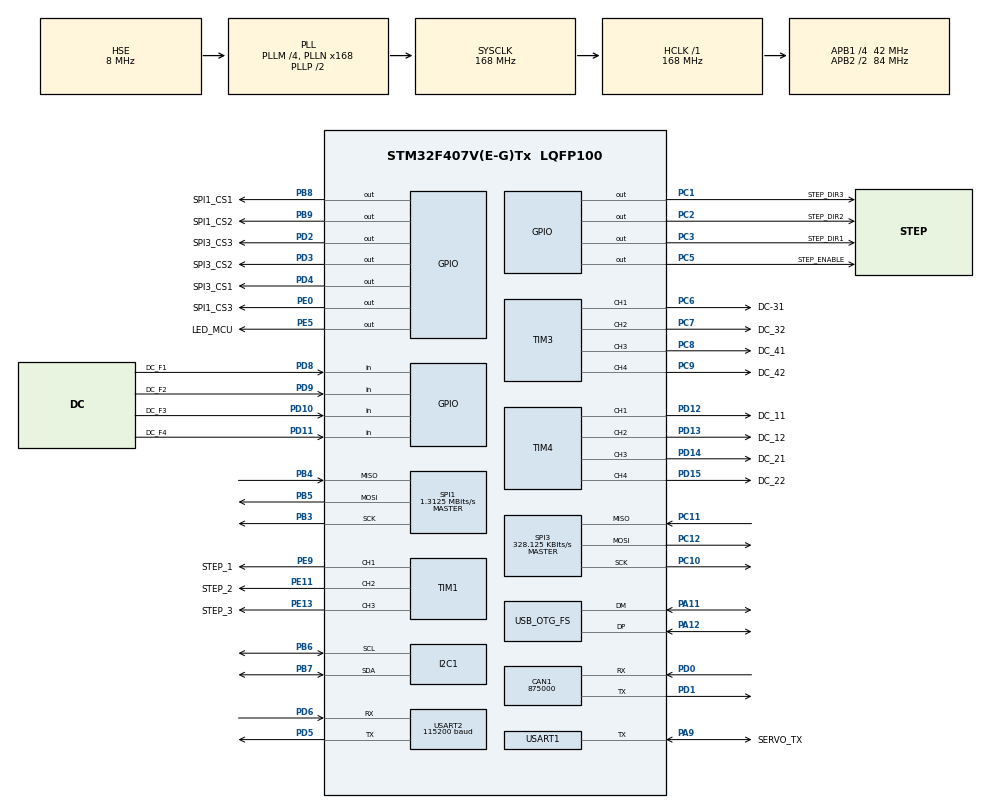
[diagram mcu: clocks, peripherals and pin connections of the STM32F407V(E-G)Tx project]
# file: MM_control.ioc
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CAN1.CalculateBaudRate=875000
CAN1.CalculateTimeBit=1142
CAN1.CalculateTimeQuantum=380.95238095238096
Dma.Request0=USART1_TX
Dma.Request1=USART1_RX
Dma.Request2=SPI1_RX
Dma.Request3=SPI1_TX
Dma.SPI1_RX.2.Direction=DMA_PERIPH_TO_MEMORY
Dma.SPI1_RX.2.FIFOMode=DMA_FIFOMODE_DISABLE
Dma.SPI1_RX.2.Instance=DMA2_Stream0
Dma.SPI1_RX.2.MemDataAlignment=DMA_MDATAALIGN_BYTE
Dma.SPI1_RX.2.MemInc=DMA_MINC_ENABLE
Dma.SPI1_RX.2.Mode=DMA_NORMAL
Dma.SPI1_RX.2.PeriphDataAlignment=DMA_PDATAALIGN_BYTE
Dma.SPI1_RX.2.PeriphInc=DMA_PINC_DISABLE
Dma.SPI1_RX.2.Priority=DMA_PRIORITY_HIGH
Dma.SPI1_TX.3.Direction=DMA_MEMORY_TO_PERIPH
Dma.SPI1_TX.3.FIFOMode=DMA_FIFOMODE_DISABLE
Dma.SPI1_TX.3.Instance=DMA2_Stream3
Dma.SPI1_TX.3.MemDataAlignment=DMA_MDATAALIGN_BYTE
Dma.SPI1_TX.3.MemInc=DMA_MINC_ENABLE
Dma.SPI1_TX.3.Mode=DMA_NORMAL
Dma.SPI1_TX.3.PeriphDataAlignment=DMA_PDATAALIGN_BYTE
Dma.SPI1_TX.3.PeriphInc=DMA_PINC_DISABLE
Dma.SPI1_TX.3.Priority=DMA_PRIORITY_HIGH
Dma.USART1_RX.1.Direction=DMA_PERIPH_TO_MEMORY
Dma.USART1_RX.1.FIFOMode=DMA_FIFOMODE_DISABLE
Dma.USART1_RX.1.Instance=DMA2_Stream2
Dma.USART1_RX.1.MemDataAlignment=DMA_MDATAALIGN_BYTE
Dma.USART1_RX.1.MemInc=DMA_MINC_ENABLE
Dma.USART1_RX.1.Mode=DMA_NORMAL
Dma.USART1_RX.1.PeriphDataAlignment=DMA_PDATAALIGN_BYTE
Dma.USART1_RX.1.PeriphInc=DMA_PINC_DISABLE
Dma.USART1_RX.1.Priority=DMA_PRIORITY_LOW
Dma.USART1_TX.0.Direction=DMA_MEMORY_TO_PERIPH
Dma.USART1_TX.0.FIFOMode=DMA_FIFOMODE_DISABLE
Dma.USART1_TX.0.Instance=DMA2_Stream7
Dma.USART1_TX.0.MemDataAlignment=DMA_MDATAALIGN_BYTE
Dma.USART1_TX.0.MemInc=DMA_MINC_ENABLE
Dma.USART1_TX.0.Mode=DMA_NORMAL
Dma.USART1_TX.0.PeriphDataAlignment=DMA_PDATAALIGN_BYTE
Dma.USART1_TX.0.PeriphInc=DMA_PINC_DISABLE
Dma.USART1_TX.0.Priority=DMA_PRIORITY_LOW
FREERTOS.Tasks01=Task1,24,128,StartDefaultTask,Default,NULL,Dynamic,NULL,NULL
FREERTOS.configENABLE_FPU=1
Mcu.Family=STM32F4
Mcu.Name=STM32F407V(E-G)Tx
Mcu.Package=LQFP100
NVIC.DMA2_Stream0_IRQn=true\:6\:0\:true\:false\:true\:true\:false\:true\:true
NVIC.DMA2_Stream2_IRQn=true\:5\:0\:false\:false\:true\:true\:false\:true\:true
NVIC.DMA2_Stream3_IRQn=true\:5\:0\:false\:false\:true\:true\:false\:true\:true
NVIC.DMA2_Stream7_IRQn=true\:5\:0\:false\:false\:true\:true\:false\:true\:true
NVIC.OTG_FS_IRQn=true\:6\:0\:true\:false\:true\:true\:false\:true\:true
NVIC.PriorityGroup=NVIC_PRIORITYGROUP_4
NVIC.SPI1_IRQn=true\:5\:0\:false\:false\:true\:true\:true\:true\:true
NVIC.SPI3_IRQn=true\:5\:0\:false\:false\:true\:true\:true\:true\:true
NVIC.TIM1_BRK_TIM9_IRQn=true\:6\:0\:true\:false\:true\:true\:true\:true\:true
NVIC.TIM1_UP_TIM10_IRQn=true\:5\:0\:false\:false\:true\:true\:true\:true\:true
NVIC.TIM3_IRQn=true\:6\:0\:true\:false\:true\:true\:true\:true\:true
NVIC.TIM4_IRQn=true\:5\:0\:false\:false\:true\:true\:true\:true\:true
NVIC.TIM8_TRG_COM_TIM14_IRQn=true\:5\:0\:false\:false\:true\:false\:false\:true\:true
NVIC.TimeBase=TIM8_TRG_COM_TIM14_IRQn
NVIC.TimeBaseIP=TIM14
NVIC.USART1_IRQn=true\:5\:0\:false\:false\:true\:true\:true\:true\:true
NVIC.USART2_IRQn=true\:5\:0\:false\:false\:true\:true\:true\:true\:true
PA11.Mode=Device_Only
PA11.Signal=USB_OTG_FS_DM
PA12.Mode=Device_Only
PA12.Signal=USB_OTG_FS_DP
PA13.Mode=Serial_Wire
PA13.Signal=SYS_JTMS-SWDIO
PA14.Mode=Serial_Wire
PA14.Signal=SYS_JTCK-SWCLK
PA9.GPIO_Label=SERVO_TX
PA9.Mode=Half_duplex(single_wire_mode)
PA9.Signal=USART1_TX
PB3.Mode=Full_Duplex_Master
PB3.Signal=SPI1_SCK
PB4.Mode=Full_Duplex_Master
PB4.Signal=SPI1_MISO
PB5.Mode=Full_Duplex_Master
PB5.Signal=SPI1_MOSI
PB6.Mode=I2C
PB6.Signal=I2C1_SCL
PB7.Mode=I2C
PB7.Signal=I2C1_SDA
PB8.GPIO_Label=SPI1_CS1
PB8.GPIO_Speed=GPIO_SPEED_FREQ_HIGH
PB8.PinState=GPIO_PIN_SET
PB8.Signal=GPIO_Output
PB9.GPIO_Label=SPI1_CS2
PB9.GPIO_Speed=GPIO_SPEED_FREQ_HIGH
PB9.PinState=GPIO_PIN_SET
PB9.Signal=GPIO_Output
PC1.GPIO_Label=STEP_DIR3
PC1.Signal=GPIO_Output
PC10.Mode=Full_Duplex_Master
PC10.Signal=SPI3_SCK
PC11.GPIO_PuPd=GPIO_PULLUP
PC11.Mode=Full_Duplex_Master
PC11.Signal=SPI3_MISO
PC12.Mode=Full_Duplex_Master
PC12.Signal=SPI3_MOSI
PC2.GPIO_Label=STEP_DIR2
PC2.Signal=GPIO_Output
PC3.GPIO_Label=STEP_DIR1
PC3.Signal=GPIO_Output
PC5.GPIO_Label=STEP_ENABLE
PC5.Signal=GPIO_Output
PC6.GPIO_Label=DC-31
PC6.Signal=S_TIM3_CH1
PC7.GPIO_Label=DC_32
PC7.Signal=S_TIM3_CH2
PC8.GPIO_Label=DC_41
PC8.Signal=S_TIM3_CH3
PC9.GPIO_Label=DC_42
PC9.Signal=S_TIM3_CH4
PD0.Mode=CAN_Activate
PD0.Signal=CAN1_RX
PD1.Mode=CAN_Activate
PD1.Signal=CAN1_TX
PD10.GPIO_Label=DC_F3
PD10.GPIO_PuPd=GPIO_PULLUP
PD10.Signal=GPIO_Input
PD11.GPIO_Label=DC_F4
PD11.GPIO_PuPd=GPIO_PULLUP
PD11.Signal=GPIO_Input
PD12.GPIO_Label=DC_11
PD12.Signal=S_TIM4_CH1
PD13.GPIO_Label=DC_12
PD13.Signal=S_TIM4_CH2
PD14.GPIO_Label=DC_21
PD14.Signal=S_TIM4_CH3
PD15.GPIO_Label=DC_22
PD15.Signal=S_TIM4_CH4
PD2.GPIO_Label=SPI3_CS3
PD2.GPIO_Speed=GPIO_SPEED_FREQ_HIGH
PD2.PinState=GPIO_PIN_SET
PD2.Signal=GPIO_Output
PD3.GPIO_Label=SPI3_CS2
PD3.GPIO_Speed=GPIO_SPEED_FREQ_HIGH
PD3.PinState=GPIO_PIN_SET
PD3.Signal=GPIO_Output
PD4.GPIO_Label=SPI3_CS1
PD4.GPIO_Speed=GPIO_SPEED_FREQ_HIGH
PD4.PinState=GPIO_PIN_SET
PD4.Signal=GPIO_Output
PD5.GPIO_PuPd=GPIO_PULLUP
PD5.Mode=Asynchronous
PD5.Signal=USART2_TX
PD6.GPIO_PuPd=GPIO_PULLUP
PD6.Mode=Asynchronous
PD6.Signal=USART2_RX
PD8.GPIO_Label=DC_F1
PD8.GPIO_PuPd=GPIO_PULLUP
PD8.Signal=GPIO_Input
PD9.GPIO_Label=DC_F2
PD9.GPIO_PuPd=GPIO_PULLUP
PD9.Signal=GPIO_Input
PE0.GPIO_Label=SPI1_CS3
PE0.GPIO_Speed=GPIO_SPEED_FREQ_HIGH
PE0.PinState=GPIO_PIN_SET
PE0.Signal=GPIO_Output
PE11.GPIO_Label=STEP_2
PE11.Signal=S_TIM1_CH2
PE13.GPIO_Label=STEP_3
PE13.Signal=S_TIM1_CH3
PE5.GPIO_Label=LED_MCU
PE5.Signal=GPIO_Output
PE9.GPIO_Label=STEP_1
PE9.Signal=S_TIM1_CH1
PH0-OSC_IN.Mode=HSE-External-Oscillator
PH0-OSC_IN.Signal=RCC_OSC_IN
PH1-OSC_OUT.Mode=HSE-External-Oscillator
PH1-OSC_OUT.Signal=RCC_OSC_OUT
ProjectManager.HeapSize=0x200
ProjectManager.StackSize=0x400
ProjectManager.TargetToolchain=CMake
RCC.48MHZClocksFreq_Value=48000000
RCC.AHBFreq_Value=168000000
RCC.APB1CLKDivider=RCC_HCLK_DIV4
RCC.APB1Freq_Value=42000000
RCC.APB1TimFreq_Value=84000000
RCC.APB2CLKDivider=RCC_HCLK_DIV2
RCC.APB2Freq_Value=84000000
RCC.APB2TimFreq_Value=168000000
RCC.CortexFreq_Value=168000000
RCC.HCLKFreq_Value=168000000
RCC.HSE_VALUE=8000000
RCC.HSI_VALUE=16000000
RCC.LSE_VALUE=32768
RCC.PLLM=4
RCC.PLLN=168
RCC.PLLQ=7
RCC.SYSCLKFreq_VALUE=168000000
RCC.SYSCLKSource=RCC_SYSCLKSOURCE_PLLCLK
RCC.VCOOutputFreq_Value=336000000
SH.S_TIM1_CH1.0=TIM1_CH1,PWM Generation1 CH1
SH.S_TIM1_CH2.0=TIM1_CH2,PWM Generation2 CH2
SH.S_TIM1_CH3.0=TIM1_CH3,PWM Generation3 CH3
SH.S_TIM3_CH1.0=TIM3_CH1,PWM Generation1 CH1
SH.S_TIM3_CH2.0=TIM3_CH2,PWM Generation2 CH2
SH.S_TIM3_CH3.0=TIM3_CH3,PWM Generation3 CH3
SH.S_TIM3_CH4.0=TIM3_CH4,PWM Generation4 CH4
SH.S_TIM4_CH1.0=TIM4_CH1,PWM Generation1 CH1
SH.S_TIM4_CH2.0=TIM4_CH2,PWM Generation2 CH2
SH.S_TIM4_CH3.0=TIM4_CH3,PWM Generation3 CH3
SH.S_TIM4_CH4.0=TIM4_CH4,PWM Generation4 CH4
SPI1.BaudRatePrescaler=SPI_BAUDRATEPRESCALER_64
SPI1.CalculateBaudRate=1.3125 MBits/s
SPI1.Direction=SPI_DIRECTION_2LINES
SPI1.Mode=SPI_MODE_MASTER
SPI1.VirtualType=VM_MASTER
SPI3.BaudRatePrescaler=SPI_BAUDRATEPRESCALER_128
SPI3.CLKPhase=SPI_PHASE_2EDGE
SPI3.CLKPolarity=SPI_POLARITY_HIGH
SPI3.CalculateBaudRate=328.125 KBits/s
SPI3.Direction=SPI_DIRECTION_2LINES
SPI3.FirstBit=SPI_FIRSTBIT_LSB
SPI3.Mode=SPI_MODE_MASTER
SPI3.VirtualType=VM_MASTER
TIM1.Channel-PWM\ Generation1\ CH1=TIM_CHANNEL_1
TIM1.Channel-PWM\ Generation2\ CH2=TIM_CHANNEL_2
TIM1.Channel-PWM\ Generation3\ CH3=TIM_CHANNEL_3
TIM3.Channel-PWM\ Generation1\ CH1=TIM_CHANNEL_1
TIM3.Channel-PWM\ Generation2\ CH2=TIM_CHANNEL_2
TIM3.Channel-PWM\ Generation3\ CH3=TIM_CHANNEL_3
TIM3.Channel-PWM\ Generation4\ CH4=TIM_CHANNEL_4
TIM4.Channel-PWM\ Generation1\ CH1=TIM_CHANNEL_1
TIM4.Channel-PWM\ Generation2\ CH2=TIM_CHANNEL_2
TIM4.Channel-PWM\ Generation3\ CH3=TIM_CHANNEL_3
TIM4.Channel-PWM\ Generation4\ CH4=TIM_CHANNEL_4
USART1.BaudRate=1000000
USART1.VirtualMode=VM_ASYNC
USART2.BaudRate=115200
USART2.VirtualMode=VM_ASYNC
USB_DEVICE.CLASS_NAME_FS=CDC
USB_DEVICE.PRODUCT_STRING_CDC_FS=STM32F407VET6
USB_DEVICE.VirtualMode-CDC_FS=Cdc
USB_DEVICE.VirtualModeFS=Cdc_FS
USB_OTG_FS.VirtualMode=Device_Only
VP_FREERTOS_VS_CMSIS_V2.Mode=CMSIS_V2
VP_SYS_VS_tim14.Mode=TIM14
VP_TIM1_VS_ClockSourceINT.Mode=Internal
VP_TIM3_VS_ClockSourceINT.Mode=Internal
VP_TIM4_VS_ClockSourceINT.Mode=Internal
VP_USB_DEVICE_VS_USB_DEVICE_CDC_FS.Mode=CDC_FS
board=custom

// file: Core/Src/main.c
/* USER CODE BEGIN Header */
/**
  ******************************************************************************
  * @file           : main.c
  * @brief          : Main program body
  ******************************************************************************
  * @attention
  *
  * Copyright (c) 2026 STMicroelectronics.
  * All rights reserved.
  *
  * This software is licensed under terms that can be found in the LICENSE file
  * in the root directory of this software component.
  * If no LICENSE file comes with this software, it is provided AS-IS.
  *
  ******************************************************************************
  */
/* USER CODE END Header */
#include "main.h"
#include "cmsis_os.h"
#include "can.h"
#include "dma.h"
#include "i2c.h"
#include "spi.h"
#include "tim.h"
#include "usart.h"
#include "usb_device.h"
#include "gpio.h"

/* USER CODE BEGIN Includes */
#include "tue_stepper.h"
#include "tue_dc.h"
/* USER CODE END Includes */

/* USER CODE BEGIN PV */
volatile uint32_t tick = 0;
/* USER CODE END PV */

void SystemClock_Config(void);
void MX_FREERTOS_Init(void);

int main(void)
{

  /* MCU Configuration--------------------------------------------------------*/

  /* Reset of all peripherals, Initializes the Flash interface and the Systick. */
  HAL_Init();

  /* Configure the system clock */
  SystemClock_Config();

  /* Initialize all configured peripherals */
  MX_GPIO_Init();
  MX_DMA_Init();
  MX_TIM1_Init();
  MX_TIM3_Init();
  MX_TIM4_Init();
  MX_USART1_UART_Init();
  MX_CAN1_Init();
  MX_I2C1_Init();
  MX_SPI3_Init();
  MX_USART2_UART_Init();
  MX_SPI1_Init();
  /* USER CODE BEGIN 2 */
  /* Steppers: TIM1 becomes the 1 us step clock and the STEP pins are turned
   * into plain GPIO outputs. See docs/STEPPER_INSTRUCTION.md. */
  tue_stepper_init();

  /* DC Motors: 4 channels on TIM3 & TIM4 with DRV8872. */
  tue_dc_init();

  /* USER CODE END 2 */

  /* Init scheduler */
  osKernelInitialize();  /* Call init function for freertos objects (in cmsis_os2.c) */
  MX_FREERTOS_Init();

  /* Start scheduler */
  osKernelStart();

  /* We should never get here as control is now taken by the scheduler */

  /* Infinite loop */
  while (1)
  {

  }
}

void SystemClock_Config(void)
{
  RCC_OscInitTypeDef RCC_OscInitStruct = {0};
  RCC_ClkInitTypeDef RCC_ClkInitStruct = {0};

  /** Configure the main internal regulator output voltage
  */
  __HAL_RCC_PWR_CLK_ENABLE();
  __HAL_PWR_VOLTAGESCALING_CONFIG(PWR_REGULATOR_VOLTAGE_SCALE1);

  /** Initializes the RCC Oscillators according to the specified parameters
  * in the RCC_OscInitTypeDef structure.
  */
  RCC_OscInitStruct.OscillatorType = RCC_OSCILLATORTYPE_HSE;
  RCC_OscInitStruct.HSEState = RCC_HSE_ON;
  RCC_OscInitStruct.PLL.PLLState = RCC_PLL_ON;
  RCC_OscInitStruct.PLL.PLLSource = RCC_PLLSOURCE_HSE;
  RCC_OscInitStruct.PLL.PLLM = 4;
  RCC_OscInitStruct.PLL.PLLN = 168;
  RCC_OscInitStruct.PLL.PLLP = RCC_PLLP_DIV2;
  RCC_OscInitStruct.PLL.PLLQ = 7;
  if (HAL_RCC_OscConfig(&RCC_OscInitStruct) != HAL_OK)
  {
    Error_Handler();
  }

  /** Initializes the CPU, AHB and APB buses clocks
  */
  RCC_ClkInitStruct.ClockType = RCC_CLOCKTYPE_HCLK|RCC_CLOCKTYPE_SYSCLK
                              |RCC_CLOCKTYPE_PCLK1|RCC_CLOCKTYPE_PCLK2;
  RCC_ClkInitStruct.SYSCLKSource = RCC_SYSCLKSOURCE_PLLCLK;
  RCC_ClkInitStruct.AHBCLKDivider = RCC_SYSCLK_DIV1;
  RCC_ClkInitStruct.APB1CLKDivider = RCC_HCLK_DIV4;
  RCC_ClkInitStruct.APB2CLKDivider = RCC_HCLK_DIV2;

  if (HAL_RCC_ClockConfig(&RCC_ClkInitStruct, FLASH_LATENCY_5) != HAL_OK)
  {
    Error_Handler();
  }
}

/* USER CODE BEGIN 4 */
/**
  * @brief  EXTI line detection callbacks for DC motor DRV8872 fault pins.
  * @param  GPIO_Pin: Specifies the pins connected to the EXTI line.
  * @retval None
  */
void HAL_GPIO_EXTI_Callback(uint16_t GPIO_Pin)
{
  tue_dc_on_fault_exti(GPIO_Pin);
}
/* USER CODE END 4 */

void HAL_TIM_PeriodElapsedCallback(TIM_HandleTypeDef *htim)
{
  if (htim->Instance == TIM14)
  {
    HAL_IncTick();
  }
  /* USER CODE BEGIN Callback 1 */
  /* TIM1 update interrupt = one master step (returns immediately otherwise). */
  tue_stepper_on_timer_elapsed(htim);

  /* TIM3 & TIM4 update interrupt for DC motor control & ramping */
  tue_dc_on_timer_elapsed(htim);

  /* USER CODE END Callback 1 */
}

void Error_Handler(void)
{
  /* USER CODE BEGIN Error_Handler_Debug */
  /* User can add his own implementation to report the HAL error return state */
  __disable_irq();
  while (1)
  {
    HAL_GPIO_TogglePin(LED_MCU_GPIO_Port, LED_MCU_Pin);
    HAL_Delay(20);
  }
  /* USER CODE END Error_Handler_Debug */
}

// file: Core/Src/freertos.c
/* USER CODE BEGIN Header */
/**
  ******************************************************************************
  * File Name          : freertos.c
  * Description        : Code for freertos applications
  ******************************************************************************
  * @attention
  *
  * Copyright (c) 2026 STMicroelectronics.
  * All rights reserved.
  *
  * This software is licensed under terms that can be found in the LICENSE file
  * in the root directory of this software component.
  * If no LICENSE file comes with this software, it is provided AS-IS.
  *
  ******************************************************************************
  */
/* USER CODE END Header */

#include "FreeRTOS.h"
#include "task.h"
#include "main.h"
#include "cmsis_os.h"

/* USER CODE BEGIN Includes */
#include "tue_usb_binary.h"
/* USER CODE END Includes */

/* Definitions for Task1 */
osThreadId_t Task1Handle;
const osThreadAttr_t Task1_attributes = {
  .name = "Task1",
  .stack_size = 128 * 4,
  .priority = (osPriority_t) osPriorityNormal,
};

void StartDefaultTask(void *argument);

extern void MX_USB_DEVICE_Init(void);
void MX_FREERTOS_Init(void); /* (MISRA C 2004 rule 8.1) */

void MX_FREERTOS_Init(void) {

  /* Create the thread(s) */
  /* creation of Task1 */
  Task1Handle = osThreadNew(StartDefaultTask, NULL, &Task1_attributes);

}

void StartDefaultTask(void *argument)
{
  /* init code for USB_DEVICE */
  MX_USB_DEVICE_Init();
  /* USER CODE BEGIN StartDefaultTask */
  /* Start the binary CAN-over-USB protocol over USB CDC (Virtual COM Port).
   * It owns the Feetech STS3215 bus on USART1 (PA9, half-duplex, 1 Mbps);
   * see docs/USB_BINARY_PROTOCOL.md and the python/ client for host usage. */
  tue_usb_init();

  /* Infinite loop */
  for(;;)
  {
    // HAL_GPIO_TogglePin(LED_MCU_GPIO_Port, LED_MCU_Pin);
    // tue_dc_set_speed_all(600,600,600,600);
    // osDelay(3000);
    // HAL_GPIO_TogglePin(LED_MCU_GPIO_Port, LED_MCU_Pin);
    // tue_dc_set_speed_all(800,800,800,800);
    osDelay(500);
  }
  /* USER CODE END StartDefaultTask */
}
